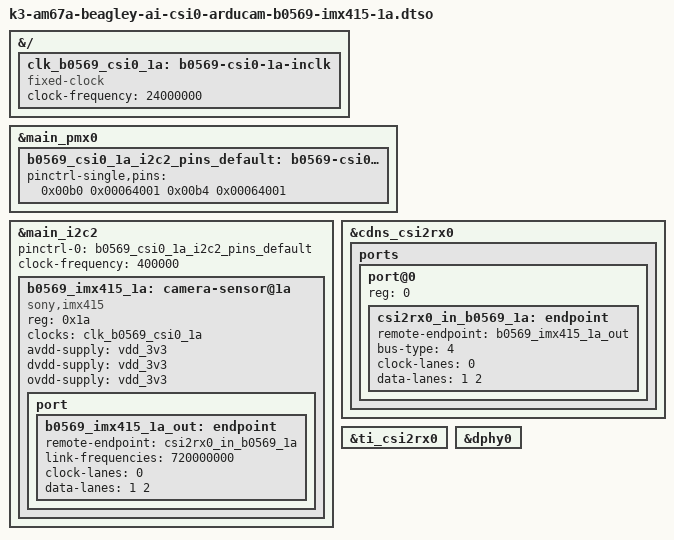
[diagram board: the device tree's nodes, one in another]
// SPDX-License-Identifier: GPL-2.0-only OR MIT
/*
 * BeagleY-AI CSI0 + Arducam B0569 (Sony IMX415), provisional R0.
 *
 * Alternate address variant for live bring-up:
 *   sensor:           Sony IMX415
 *   I2C:              0x1a on main_i2c2 (verify on hardware)
 *   input clock:      24 MHz
 *   CSI-2 data lanes: 1, 2
 *   link frequency:   720 MHz (1.44 Gb/s per lane DDR)
 *   sensor output:    3864x2192 SGBRG10, about 30 fps
 *
 * reset-gpios is intentionally omitted in R0 because reset is optional in the
 * driver and B0569 connector/XCLR wiring is not yet verified on BeagleY-AI.
 * The three supply requests are provisionally parented to the connector 3.3-V
 * rail, assuming B0569 provides local sensor regulation.
 */
/dts-v1/;
/plugin/;

&{/} {
	clk_b0569_csi0_1a: b0569-csi0-1a-inclk {
		compatible = "fixed-clock";
		#clock-cells = <0>;
		clock-frequency = <24000000>;
	};
};

&main_pmx0 {
	b0569_csi0_1a_i2c2_pins_default: b0569-csi0-1a-i2c2-default-pins {
		pinctrl-single,pins = <
			0x00b0 0x00064001
			0x00b4 0x00064001
		>;
	};
};

&main_i2c2 {
	pinctrl-names = "default";
	pinctrl-0 = <&b0569_csi0_1a_i2c2_pins_default>;
	clock-frequency = <400000>;
	#address-cells = <1>;
	#size-cells = <0>;
	status = "okay";

	b0569_imx415_1a: camera-sensor@1a {
		compatible = "sony,imx415";
		reg = <0x1a>;

		clocks = <&clk_b0569_csi0_1a>;
		clock-names = "inck";

		avdd-supply = <&vdd_3v3>;
		dvdd-supply = <&vdd_3v3>;
		ovdd-supply = <&vdd_3v3>;

		port {
			b0569_imx415_1a_out: endpoint {
				remote-endpoint = <&csi2rx0_in_b0569_1a>;
				link-frequencies = /bits/ 64 <720000000>;
				clock-lanes = <0>;
				data-lanes = <1 2>;
			};
		};
	};
};

&cdns_csi2rx0 {
	ports {
		#address-cells = <1>;
		#size-cells = <0>;

		port@0 {
			reg = <0>;
			status = "okay";

			csi2rx0_in_b0569_1a: endpoint {
				remote-endpoint = <&b0569_imx415_1a_out>;
				bus-type = <4>;
				clock-lanes = <0>;
				data-lanes = <1 2>;
			};
		};
	};
};

&ti_csi2rx0 {
	status = "okay";
};

&dphy0 {
	status = "okay";
};
